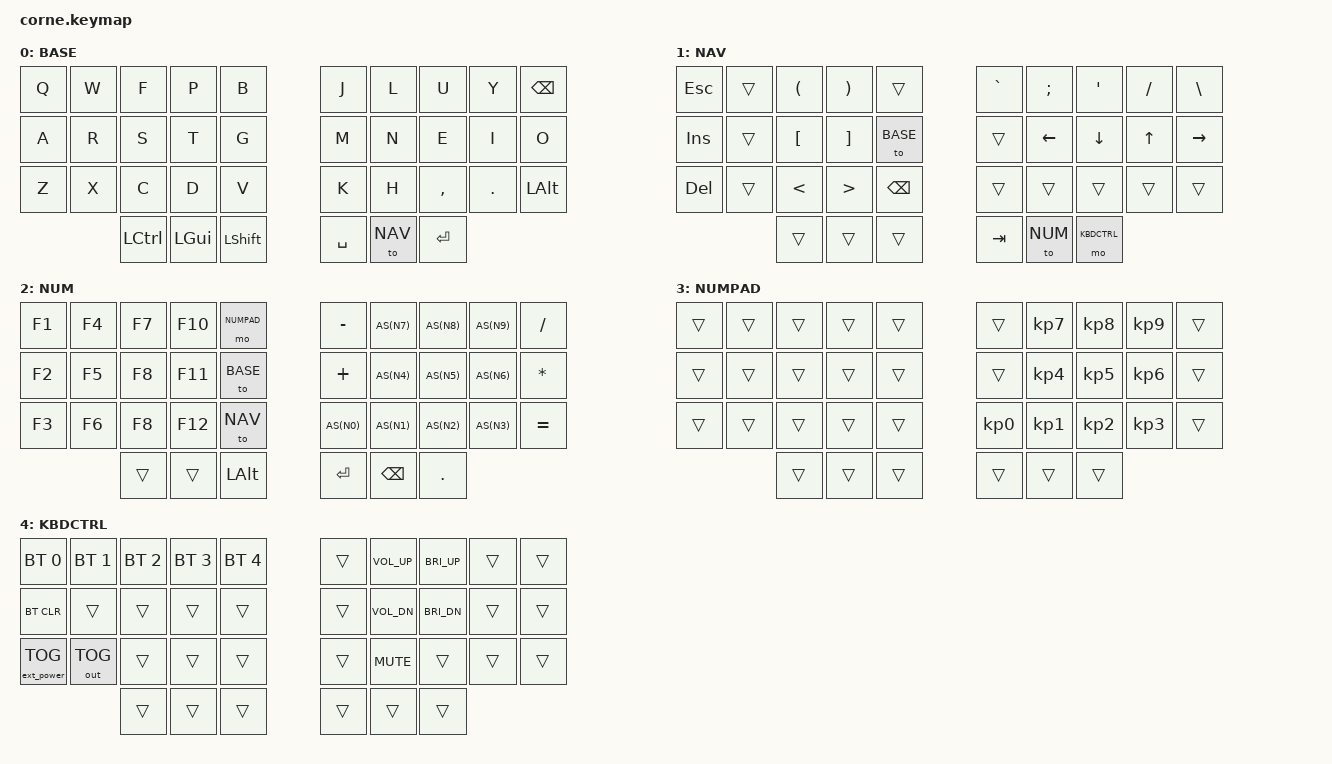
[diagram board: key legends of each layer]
/*
 * Copyright (c) 2020 The ZMK Contributors
 *
 * SPDX-License-Identifier: MIT
 */

#include <behaviors.dtsi>
#include <dt-bindings/zmk/keys.h>
#include <dt-bindings/zmk/bt.h>
#include <dt-bindings/zmk/outputs.h>
#include <dt-bindings/zmk/ext_power.h>

// placeholders
#define ___ &trans
#define XXX &none

// Layer defines
#define BASE 0
#define NAV 1
#define NUM 2
#define NUMPAD 3
#define KBDCTRL 4

#define AS(keycode) &as LS(keycode) keycode

/ {
    chosen {
      zmk,physical-layout = &foostan_corne_5col_layout;
    };

    behaviors {
    as: auto_shift {
            compatible = "zmk,behavior-hold-tap";
            #binding-cells = <2>;
            tapping_term_ms = <200>;
            quick_tap_ms = <0>;
            flavor = "tap-preferred";
            bindings = <&kp>, <&kp>;
        };
    };

    keymap {
            compatible = "zmk,keymap";

// --------------------------------------------------------------------
// |  Q  |  W  |  F   |  P     |  B     |     |  J  |  L   |  U   |  Y   | - |
// |  A  |  R  |  S   |  T     |  G     |     |  M  |  N   |  E   |  I   | O |
// |  Z  |  X  |  C   |  D     |  V     |     |  K  |  H   | -    | -    | . |
//             | LCTRL|  LGUI  | LSHIFT |     | -   | -    | -    |           
            colemakdh {  
                        display-name = "BASE";
                        bindings = <          
   &kp Q &kp W &kp F     &kp P    &kp B          &kp J     &kp L   &kp U     &kp Y   &kp BSPC
   &kp A &kp R &kp S     &kp T    &kp G          &kp M     &kp N   &kp E     &kp I   &kp O    
   &kp Z &kp X &kp C     &kp D    &kp V          &kp K     &kp H   &kp COMMA &kp DOT &kp LALT 
               &kp LCTRL &kp LGUI &kp LSHFT      &kp SPACE &to NAV &kp RET      
                        >; 
                };

// --------------------------------------------------------------------
// |  -  |  -  |  -  |  -  |  -  |     |  -  |  -      |  KP_7  |  KP_8  | KP_9 |
// |  -  |  -  |  -  |  -  |  -  |     |  -  |  -      |  KP_4  |  KP_5  | KP_6 |
// |  -  |  -  |  -  |  -  |  -  |     |  -  |  KP_0   |  KP_1  |  KP_2  | KP_3 |
//             | -   | -   | -   |     | -   | -       | -      |           
                nav { 
                        display-name = "NAV"; 
                        bindings = <       
   &kp ESC    ___ &kp LPAR &kp RPAR ___            &kp GRAVE &kp SEMI  &kp SQT     &kp SLASH &kp BSLH   
   &kp INSERT ___ &kp LBKT &kp RBKT &to BASE       ___       &kp LEFT  &kp DOWN    &kp UP    &kp RIGHT 
   &kp DELETE ___ &kp LT   &kp GT   &kp BSPC       ___       ___       ___         ___       ___  
                  ___      ___      ___            &kp TAB   &to NUM   &mo KBDCTRL      
                        >;
                };

// --------------------------------------------------------------------
// |  F1  |  F4  |  F7  |  F10  |  to QWERTY      |     |  -   |  7  |  8  | 9 |  -  |
// |  F2  |  F5  |  F8  |  F11  |  mo NUM_KEYPAD  |     |  -   |  4  |  5  | 6 |  -  |
// |  F3  |  F6  |  F9  |  F12  |  -              |     |  0   |  1  |  2  | 3 |  -  |
//               | -    | -     | -               |     | -   | -    | -   |           
                num {  
                        display-name = "NUM";                        
                        bindings = <                                    
   &kp F1 &kp F4 &kp F7 &kp F10 &mo NUMPAD  &kp MINUS  AS(N7)   AS(N8) AS(N9) &kp SLASH  
   &kp F2 &kp F5 &kp F8 &kp F11 &to BASE    &kp PLUS   AS(N4)   AS(N5) AS(N6) &kp STAR        
   &kp F3 &kp F6 &kp F8 &kp F12 &to NAV     AS(N0)     AS(N1)   AS(N2) AS(N3) &kp EQUAL        
                 ___    ___     &kp LALT    &kp RET    &kp BSPC &kp DOT                      
                        >;  
                };

// --------------------------------------------------------------------
// |  -  |  -  |  -  |  -  |  -  |     |  -      |  KP_7  |  KP_8  | KP_9 | -  |
// |  -  |  -  |  -  |  -  |  -  |     |  -      |  KP_4  |  KP_5  | KP_6 | -  |
// |  -  |  -  |  -  |  -  |  -  |     |  KP_0   |  KP_1  |  KP_2  | KP_3 | -  |
//             | -   | -   | -   |     | -       | -      | -      |           
                numpad {  
                        display-name = "NUMPAD";                        
                        bindings = <                                    
   ___ ___ ___ ___ ___   ___       &kp KP_N7 &kp KP_N8 &kp KP_N9 ___   
   ___ ___ ___ ___ ___   ___       &kp KP_N4 &kp KP_N5 &kp KP_N6 ___ 
   ___ ___ ___ ___ ___   &kp KP_N0 &kp KP_N1 &kp KP_N2 &kp KP_N3 ___ 
           ___ ___ ___   ___ ___       ___                    
                        >;  
                };

// --------------------------------------------------------------------
// |  BT1  |  BT2  |  BT3  |  BT4  |  BT5  |     |  Y  |  U   |  I   |  O   | OUT_TOG |
// |  1  |  1  |  D  |  F  |  G  |     |  H  |  J   |  K   |  L   | ' |
// |  1  |  X  |  C  |  V  |  B  |     |  N  |  M   | CTRL | META | . |
//             | GUI | LWR | SPC |     | ENT | RSE  | BSPC |
                kbdctrl {                      
                        display-name = "KBDCTRL";                               
                        bindings = <                                    
   &bt BT_SEL 0      &bt BT_SEL 1 &bt BT_SEL 2 &bt BT_SEL 3 &bt BT_SEL 4   ___ &kp C_VOL_UP &kp C_BRI_UP ___ ___   
   &bt BT_CLR        ___          ___          ___          ___            ___ &kp C_VOL_DN &kp C_BRI_DN ___ ___ 
   &ext_power EP_TOG &out OUT_TOG          ___          ___          ___            ___ &kp C_MUTE   ___          ___ ___ 
                                 ___          ___          ___            ___ ___          ___                    
                        >;                                              
                };
    };
};
